# ESP32-H2 register map
Vendor: ESPRESSIF SYSTEMS (SHANGHAI) CO., LTD.; Series: ESP32 H-Series; File version: 12
CPU: RV32IMAC r0p0, little endian, no MPU, no FPU, 0 interrupt priority bits
Address unit: 32 bits
Registers are 32-bit, read-write, reset 0x0 unless marked. A register's access mark holds for its fields unless they carry their own. Offsets are from the block's base; [hi:lo] are bit positions; lines under a group give offsets from that group; {n}, {i} and the like mark numbered series.

## LP_AON — LP_AON Peripheral
Base 0x600B1000
{0x0+4i} STORE{i} (i=0..9) — need_des
  [31:0] DATA
0x28 GPIO_MUX — need_des
  [7:0] SEL
0x2C GPIO_HOLD0 — need_des
0x30 GPIO_HOLD1 — need_des
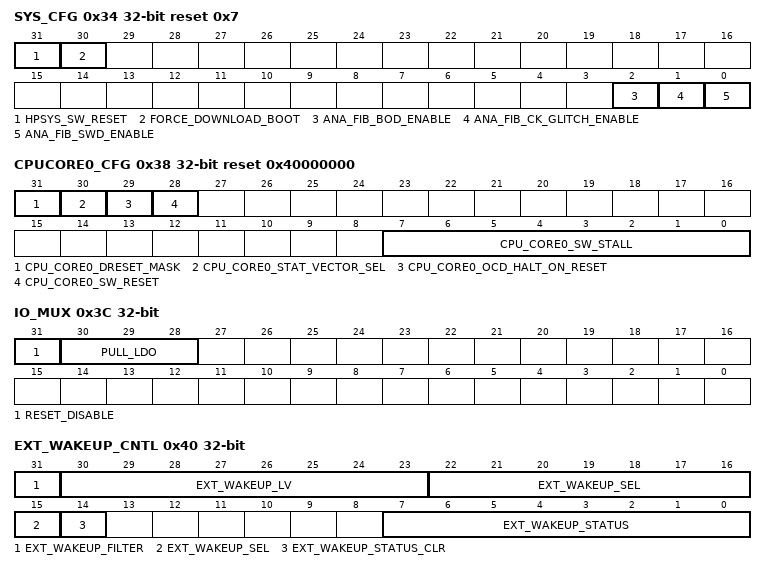
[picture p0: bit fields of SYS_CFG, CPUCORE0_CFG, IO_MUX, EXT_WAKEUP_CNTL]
0x34 SYS_CFG access per field reset 0x7 — need_des
  [31] HPSYS_SW_RESET wo — need_des
  [30] FORCE_DOWNLOAD_BOOT rw — need_des
  [2] ANA_FIB_BOD_ENABLE ro — need_des
  [1] ANA_FIB_CK_GLITCH_ENABLE ro — need_des
  [0] ANA_FIB_SWD_ENABLE ro — need_des
0x38 CPUCORE0_CFG access per field reset 0x40000000 — need_des
  [31] CPU_CORE0_DRESET_MASK rw — need_des
  [30] CPU_CORE0_STAT_VECTOR_SEL rw — need_des
  [29] CPU_CORE0_OCD_HALT_ON_RESET rw — need_des
  [28] CPU_CORE0_SW_RESET wo — need_des
  [7:0] CPU_CORE0_SW_STALL rw — need_des
0x3C IO_MUX — need_des
  [31] RESET_DISABLE — need_des
  [30:28] PULL_LDO — need_des
0x40 EXT_WAKEUP_CNTL access per field — need_des
  [31] EXT_WAKEUP_FILTER rw — need_des
  [30:23] EXT_WAKEUP_LV rw — need_des
  [22:15] EXT_WAKEUP_SEL rw — need_des
  [14] EXT_WAKEUP_STATUS_CLR wo — need_des
  [7:0] EXT_WAKEUP_STATUS ro — need_des
0x44 USB — need_des
  [31] RESET_DISABLE
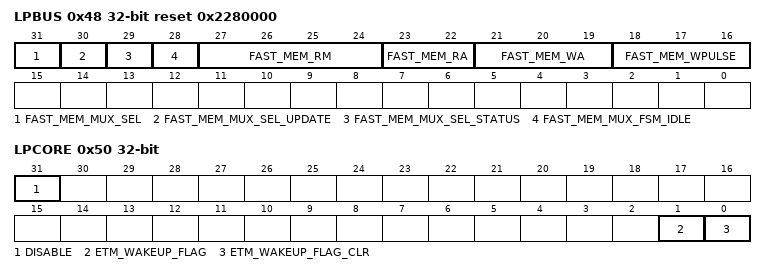
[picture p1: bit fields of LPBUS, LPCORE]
0x48 LPBUS access per field reset 0x2280000 — need_des
  [31] FAST_MEM_MUX_SEL ro — reserved
  [30] FAST_MEM_MUX_SEL_UPDATE ro — reserved
  [29] FAST_MEM_MUX_SEL_STATUS ro — reserved
  [28] FAST_MEM_MUX_FSM_IDLE ro — reserved
  [27:24] FAST_MEM_RM rw — This field controls fast memory RM parameter. 0b0011 for 1.1V operating Voltage, 0b0010 for 1.0V, 0b0000 for 0.9V.
  [23:22] FAST_MEM_RA rw — This field controls fast memory RA parameter. 0b00 for 1.1V/1.0V operating Voltage, 0b01 for 0.9V.
  [21:19] FAST_MEM_WA rw — This field controls fast memory WA parameter. 0b100 for 1.1V operating Voltage, 0b101 for 1.0V, 0b110 for 0.9V.
  [18:16] FAST_MEM_WPULSE rw — This field controls fast memory WPULSE parameter. 0b000 for 1.1V/1.0V/0.9V operating Voltage.
0x4C SDIO_ACTIVE reset 0x2800000 — need_des
  [31:22] SDIO_ACT_DNUM
0x50 LPCORE access per field — need_des
  [31] DISABLE rw — need_des
  [1] ETM_WAKEUP_FLAG rw — need_des
  [0] ETM_WAKEUP_FLAG_CLR wo — need_des
0x54 SAR_CCT — need_des
  [31:29] SAR2_PWDET_CCT
0x58 JTAG_SEL reset 0x80000000 — need_des
  [31] SOFT — If strapping_sel_jtag feature is disabled by efuse, and if neither pad_jtag or usb_jtag is disabled by efuse, this field determines which one jtag between usb_jtag and pad_jtag will be used. 1'b1(default): usb_jtag, 1'b0: pad_jtag.
0x3FC DATE — need_des

## LP_APM — Low-power Access Permission Management Controller
Base 0x600B3800
0x00 REGION_FILTER_EN reset 0x1 — Region filter enable register
  [1:0] REGION_FILTER_EN — Region filter enable
{0x4+0xC*i} REGION{i} (i=0..1) group — Cluster REGION{i}, containing REGION*_ADDR_START, REGION*_ADDR_END, REGION*_PMS_ATTR
  0x00 ADDR_START — Region address register
    [31:0] ADDR_START — Start address of region0
  0x04 ADDR_END reset 0xFFFFFFFF — Region address register
    [31:0] ADDR_END — End address of region0
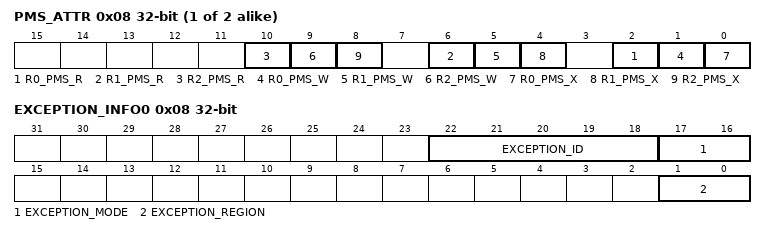
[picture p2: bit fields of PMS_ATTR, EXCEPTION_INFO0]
  0x08 PMS_ATTR — Region access authority attribute register
    [4n+2] R{n}_PMS_R (n=0..2) — Region read authority in REE_MODE{n}
    [4n+1] R{n}_PMS_W (n=0..2) — Region write authority in REE_MODE{n}
    [4n] R{n}_PMS_X (n=0..2) — Region execute authority in REE_MODE{n}
0xC4 FUNC_CTRL reset 0x1 — PMS function control register
  [n] M{n}_PMS_FUNC_EN (n=0..0) — PMS M{n} function enable
{0xC8+0x10*i} M{i} (i=0..0) group — Cluster M{i}, containing M?_STATUS, M?_STATUS_CLR, M?_EXCEPTION_INFO0, M?_EXCEPTION_INFO1
  0x00 STATUS ro — M0 status register
    [1:0] EXCEPTION_STATUS
  0x04 STATUS_CLR wo — M0 status clear register
    [0] REGION_STATUS_CLR — Clear exception status
  0x08 EXCEPTION_INFO0 ro — M0 exception_info0 register
    [22:18] EXCEPTION_ID — Exception id information
    [17:16] EXCEPTION_MODE
    [1:0] EXCEPTION_REGION
  0x0C EXCEPTION_INFO1 ro — M0 exception_info1 register
    [31:0] EXCEPTION_ADDR
0xE8 INT_EN — APM interrupt enable register
  [n] M{n}_APM (n=0..0) — APM M{n} interrupt enable
0xEC CLOCK_GATE reset 0x1 — clock gating register
  [0] CLK_EN — reg_clk_en
0xFC DATE — Version register
